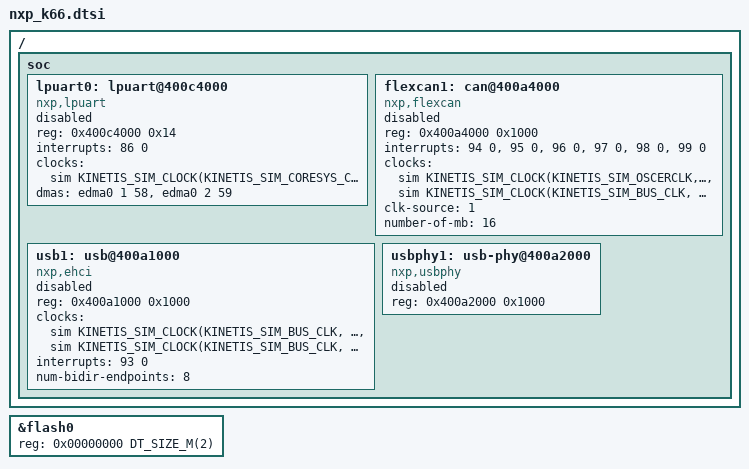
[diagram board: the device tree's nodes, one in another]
/*
 * Copyright (c) 2020 DENX Software Engineering GmbH
 *
 * SPDX-License-Identifier: Apache-2.0
 */

#include <mem.h>
#include <freq.h>
#include <nxp/kinetis/nxp_k6x.dtsi>

&flash0 {
	reg = <0x00000000 DT_SIZE_M(2)>;
};

/ {
	soc {
		lpuart0: lpuart@400c4000 {
			compatible = "nxp,lpuart";
			reg = <0x400c4000 0x14>;
			interrupts = <86 0>;
			clocks = <&sim KINETIS_SIM_CLOCK(KINETIS_SIM_CORESYS_CLK, 0x1038, 20)>;
			dmas = <&edma0 1 58>, <&edma0 2 59>;
			dma-names = "rx", "tx";
			status = "disabled";
		};

		flexcan1: can@400a4000 {
			compatible = "nxp,flexcan";
			reg = <0x400a4000 0x1000>;
			interrupts = <94 0>, <95 0>, <96 0>, <97 0>, <98 0>, <99 0>;
			interrupt-names = "mb-0-15", "bus-off", "error", "tx-warning",
					  "rx-warning", "wake-up";
			clocks = <&sim KINETIS_SIM_CLOCK(KINETIS_SIM_OSCERCLK, 0x1030, 4)>,
				 <&sim KINETIS_SIM_CLOCK(KINETIS_SIM_BUS_CLK, 0x1030, 4)>;
			clock-names = "clksrc0", "clksrc1";
			clk-source = <1>;
			number-of-mb = <16>;
			status = "disabled";
		};

		usb1: usb@400a1000 {
			compatible = "nxp,ehci";
			reg = <0x400a1000 0x1000>;
			// current mcux_ehci wants to get both as 0/1 _here_ not separately in the phy node
			clocks = <&sim KINETIS_SIM_CLOCK(KINETIS_SIM_BUS_CLK, 0x1030, 1)>,
				<&sim KINETIS_SIM_CLOCK(KINETIS_SIM_BUS_CLK, 0x1030, 2)>;
			//clock-names = "clk_scgc3";
			// I think it wants a clock-rates?
			// preinit will set rate if clock and clock-rates.
			// but no set_rate for anything for kx so no?
			//clock-rates = <134000000 50000000>;
			interrupts = <93 0>;
			interrupt-names = "usbhs_otg";
			num-bidir-endpoints = <8>;
			status = "disabled";
		};

		usbphy1: usb-phy@400a2000 {
			compatible = "nxp,usbphy";
			reg = <0x400a2000 0x1000>;
			//clocks = <&sim KINETIS_SIM_CLOCK(KINETIS_SIM_BUS_CLK, 0x1030, 2)>;
			//clock-names = "clk_scgc3";
			status = "disabled";
		};

	};
};
